# ODS5010 register map
Vendor: OCS; Series: ODS5010; File version: 1.0
CPU: CM0plus r0p0, little endian, MPU, FPU, 4 interrupt priority bits
Registers are 32-bit, read-write, reset 0x0 unless marked. A register's access mark holds for its fields unless they carry their own. Offsets are from the block's base; [hi:lo] are bit positions; {n}, {i} and the like mark numbered series.

## MCPWM — Motor Control PWM
Base 0x40010C00; register names take the prefix MCPWM_
0x00 TH00 — MCPWM CH0_P Compare Threshold Register
  [31:0] TH00 — CH0_P Compare Threshold Value
0x04 TH01 — MCPWM CH0_N Compare Threshold Register
  [31:0] TH01 — CH0_N Compare Threshold Value
0x08 TH10 — MCPWM CH1_P Compare Threshold Register
  [31:0] TH10 — CH1_P Compare Threshold Value
0x0C TH11 — MCPWM CH1_N Compare Threshold Register
  [31:0] TH11 — CH1_N Compare Threshold Value
0x10 TH20 — MCPWM CH2_P Compare Threshold Register
  [31:0] TH20 — CH2_P Compare Threshold Value
0x14 TH21 — MCPWM CH2_N Compare Threshold Register
  [31:0] TH21 — CH2_N Compare Threshold Value
0x18 TH30 — MCPWM CH3_P Compare Threshold Register
  [31:0] TH30 — CH3_P Compare Threshold Value
0x1C TH31 — MCPWM CH3_N Compare Threshold Register
  [31:0] TH31 — CH3_N Compare Threshold Value
0x20 TH40 — MCPWM CH4_P Compare Threshold Register
  [31:0] TH40 — CH4_P Compare Threshold Value
0x24 TH41 — MCPWM CH4_N Compare Threshold Register
  [31:0] TH41 — CH4_N Compare Threshold Value
0x28 TH50 — MCPWM CH5_P Compare Threshold Register
  [31:0] TH50 — CH5_P Compare Threshold Value
0x2C TH51 — MCPWM CH5_N Compare Threshold Register
  [31:0] TH51 — CH5_N Compare Threshold Value
{0x30+4i} TMR{i} (i=0..3) — ADC Sample Timer Compare Threshold {i} Register
  [31:0] TMR{i} — ADC Sample Timer Compare Threshold {i}
0x40 TH0 — MCPWM Time Base 0 Threshold Register
  [31:0] TH0 — Time Base 0 Threshold Value
0x44 TH1 — MCPWM Time Base 1 Threshold Register
  [31:0] TH1 — Time Base 1 Threshold Value
0x48 CNT0 ro — MCPWM Time Base 0 Counter Register
  [31:0] CNT0 — Time Base 0 Counter Value
0x4C CNT1 ro — MCPWM Time Base 1 Counter Register
  [31:0] CNT1 — Time Base 1 Counter Value
0x50 UPDATE — MCPWM Load Control Register
  [31:0] UPDATE — Load Control
0x54 FCNT ro — MCPWM FAIL Time Counter Value
  [31:0] FCNT — FAIL Time Counter Value
0x58 EVT0 — MCPWM Time Base 0 External Trigger
  [31:0] EVT0 — Time Base 0 External Trigger
0x5C EVT1 — MCPWM Time Base 1 External Trigger
  [31:0] EVT1 — Time Base 1 External Trigger
0x60 DTH00 — MCPWM CH0/1/2 N Channel Dead Time Control Register
  [31:0] DTH00 — CH0/1/2 N Channel Dead Time Width
0x64 DTH01 — MCPWM CH0/1/2 P Channel Dead Time Control Register
  [31:0] DTH01 — CH0/1/2 P Channel Dead Time Width
0x68 DTH10 — MCPWM CH3/4/5 N Channel Dead Time Control Register
  [31:0] DTH10 — CH3/4/5 N Channel Dead Time Width
0x6C DTH11 — MCPWM CH3/4/5 P Channel Dead Time Control Register
  [31:0] DTH11 — CH3/4/5 P Channel Dead Time Width
0x70 FLT — MCPWM Filter Clock Divider Register
  [31:0] FLT — Filter Clock Divider
0x74 SDCFG — MCPWM Load Configuration Register
  [31:0] SDCFG — Load Configuration
0x78 AUEN — MCPWM Auto Update Enable Register
  [31:0] AUEN — Auto Update Enable
0x7C TCLK — MCPWM Clock Divider Control Register
  [31:0] TCLK — Clock Divider Control
0x80 IE0 — MCPWM Time Base 0 Interrupt Control Register
  [31:0] IE0 — Time Base 0 Interrupt Control
0x84 IF0 — MCPWM Time Base 0 Interrupt Flag Register
  [31:0] IF0 — Time Base 0 Interrupt Flags
0x88 IE1 — MCPWM Interrupt Control Register
  [31:0] IE1 — Interrupt Control
0x8C IF1 — MCPWM Interrupt Flag Register
  [31:0] IF1 — Interrupt Flags
0x90 EIE — MCPWM Exception Interrupt Control Register
  [31:0] EIE — Exception Interrupt Control
0x94 EIF — MCPWM Exception Interrupt Flag Register
  [31:0] EIF — Exception Interrupt Flags
0x98 RE — MCPWM DMA Request Control Register
  [31:0] RE — DMA Request Control
0x9C PP — MCPWM Push-Pull Mode Enable Register
  [31:0] PP — Push-Pull Mode Enable
0xA0 IO01 — MCPWM CH0 CH1 IO Control Register
  [31:0] IO01 — CH0 and CH1 IO Control
0xA4 IO23 — MCPWM CH2 CH3 IO Control Register
  [31:0] IO23 — CH2 and CH3 IO Control
0xA8 IO45 — MCPWM CH4 CH5 IO Control Register
  [31:0] IO45 — CH4 and CH5 IO Control
0xB0 FAIL012 — MCPWM CH0 CH1 CH2 Short Circuit Control Register
  [31:0] FAIL012 — CH0/1/2 Short Circuit Control
0xB4 FAIL345 — MCPWM CH3 CH4 CH5 Short Circuit Control Register
  [31:0] FAIL345 — CH3/4/5 Short Circuit Control
0xB8 CH_DEF — MCPWM Short Circuit Protection Channel Output Default Value
  [31:0] CH_DEF — Channel Output Default Value
0xBC CH_MSK — MCPWM Channel Mask Register
  [31:0] CH_MSK — Channel Mask
0xC0 PRT — MCPWM Protection Register
  [31:0] PRT — Protection Control
0xC8 STT_HYST — MCPWM Status Stay Delay Register
  [31:0] STT_HYST — Status Stay Hysteresis
0xCC ZCS_DELAY — MCPWM ZCS Status Delay Register
  [31:0] ZCS_DELAY — ZCS Status Delay

## ADC — Analog-to-Digital Converter (ADC) Peripheral
Base 0x40012400; register names take the prefix ADC_
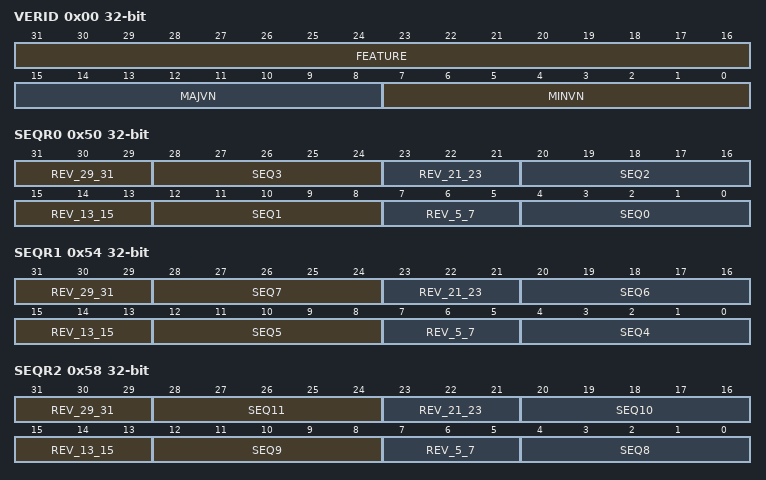
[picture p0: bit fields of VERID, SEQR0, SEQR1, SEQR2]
0x00 VERID — Version Identification Register
  [31:16] FEATURE — Feature Identification
  [15:8] MAJVN — Major Version Number
  [7:0] MINVN — Minor Version Number
{0x4+4i} DATA{i} (i=0..15) — ADC Data Register {i}
0x44 RSV0 — Reserved Register 0
0x48 TGSR — Trigger Status Register
0x4C TGNR — Trigger Number Register
0x50 SEQR0 — Sequence Control Register 0
  [31:29] REV_29_31 — Reserved Bits 29-31
  [8n+4:8n] SEQ{n} (n=0..3) — Sequence Channel {n} Selection
  [23:21] REV_21_23 — Reserved Bits 21-23
  [15:13] REV_13_15 — Reserved Bits 13-15
  [7:5] REV_5_7 — Reserved Bits 5-7
0x54 SEQR1 — Sequence Control Register 1
  [31:29] REV_29_31 — Reserved Bits 29-31
  [8n-28:8n-32] SEQ{n} (n=4..7) — Sequence Channel {n} Selection
  [23:21] REV_21_23 — Reserved Bits 21-23
  [15:13] REV_13_15 — Reserved Bits 13-15
  [7:5] REV_5_7 — Reserved Bits 5-7
0x58 SEQR2 — Sequence Control Register 2
  [31:29] REV_29_31 — Reserved Bits 29-31
  [8n-60:8n-64] SEQ{n} (n=8..11) — Sequence Channel {n} Selection
  [23:21] REV_21_23 — Reserved Bits 21-23
  [15:13] REV_13_15 — Reserved Bits 13-15
  [7:5] REV_5_7 — Reserved Bits 5-7
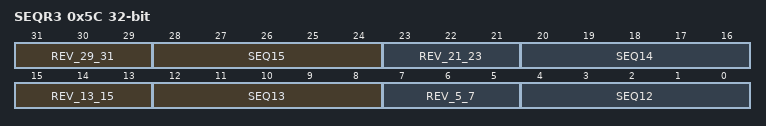
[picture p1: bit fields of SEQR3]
0x5C SEQR3 — Sequence Control Register 3
  [31:29] REV_29_31 — Reserved Bits 29-31
  [8n-92:8n-96] SEQ{n} (n=12..15) — Sequence Channel {n} Selection
  [23:21] REV_21_23 — Reserved Bits 21-23
  [15:13] REV_13_15 — Reserved Bits 13-15
  [7:5] REV_5_7 — Reserved Bits 5-7
0x60 CR — Control Register
0x64 OTR — Over Temperature Register
0x68 TCFG — Timer Configuration Register
0x6C AWTH — Analog Watchdog Threshold High Register
0x70 AWE — Analog Watchdog Enable Register
0x74 IR — Interrupt Request Register
0x78 IE — Interrupt Enable Register
0x7C RSV1 — Reserved Register 1
0x80 CALIB — Calibration Register
